VERSION "All_Common"

NS_ :

BS_:

BU_: SAS UNKNOWN

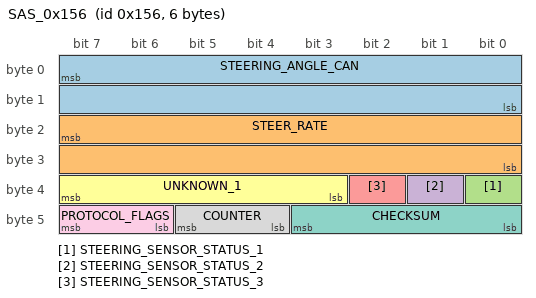
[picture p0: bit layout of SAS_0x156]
BO_ 342 SAS_0x156: 6 SAS
 SG_ STEERING_ANGLE_CAN : 7|16@0- (-0.1,0) [-3276.7000000000003|3276.8] "deg"  UNKNOWN
 SG_ STEER_RATE : 23|16@0- (-1,0) [-32767|32768] "deg/s"  UNKNOWN
 SG_ STEERING_SENSOR_STATUS_1 : 32|1@1+ (1,0) [0|1] ""  UNKNOWN
 SG_ STEERING_SENSOR_STATUS_2 : 33|1@1+ (1,0) [0|1] ""  UNKNOWN
 SG_ STEERING_SENSOR_STATUS_3 : 34|1@1+ (1,0) [0|1] ""  UNKNOWN
 SG_ UNKNOWN_1 : 35|5@1+ (1,0) [0|31] ""  UNKNOWN
 SG_ CHECKSUM : 40|4@1+ (1,0) [0|15] ""  UNKNOWN
 SG_ COUNTER : 44|2@1+ (1,0) [0|3] ""  UNKNOWN
 SG_ PROTOCOL_FLAGS : 46|2@1+ (1,0) [0|3] ""  UNKNOWN
